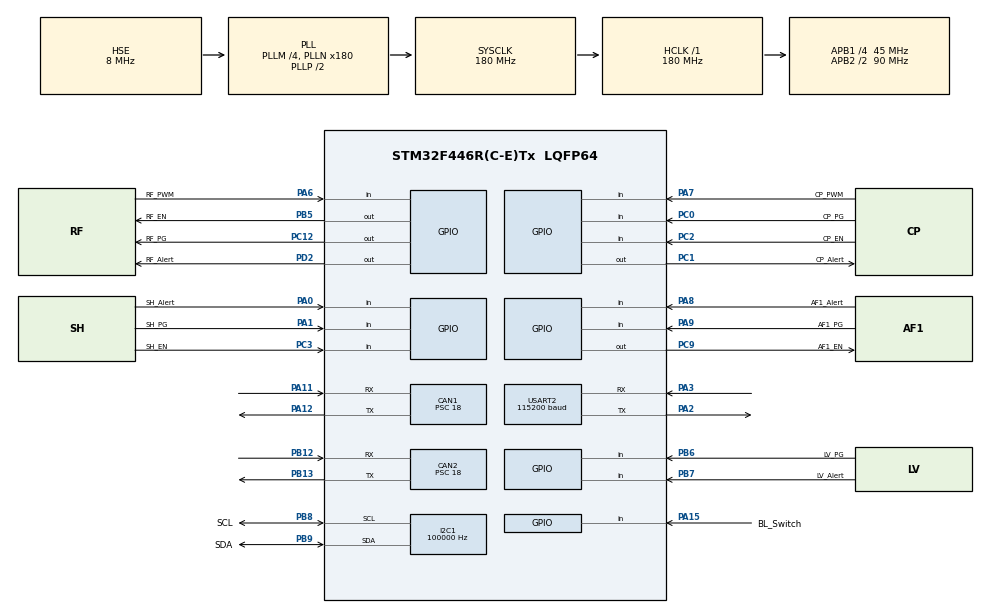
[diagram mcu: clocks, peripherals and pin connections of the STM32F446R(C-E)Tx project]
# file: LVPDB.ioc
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CAN1.BS1=CAN_BS1_3TQ
CAN1.CalculateBaudRate=500000
CAN1.CalculateTimeBit=2000
CAN1.CalculateTimeQuantum=400.0
CAN1.Mode=CAN_MODE_NORMAL
CAN1.Prescaler=18
CAN2.BS1=CAN_BS1_3TQ
CAN2.CalculateBaudRate=500000
CAN2.CalculateTimeBit=2000
CAN2.CalculateTimeQuantum=400.0
CAN2.Mode=CAN_MODE_NORMAL
CAN2.Prescaler=18
Dma.Request0=USART2_RX
Dma.Request1=USART2_TX
Dma.USART2_RX.0.Direction=DMA_PERIPH_TO_MEMORY
Dma.USART2_RX.0.FIFOMode=DMA_FIFOMODE_DISABLE
Dma.USART2_RX.0.Instance=DMA1_Stream5
Dma.USART2_RX.0.MemDataAlignment=DMA_MDATAALIGN_BYTE
Dma.USART2_RX.0.MemInc=DMA_MINC_ENABLE
Dma.USART2_RX.0.Mode=DMA_CIRCULAR
Dma.USART2_RX.0.PeriphDataAlignment=DMA_PDATAALIGN_BYTE
Dma.USART2_RX.0.PeriphInc=DMA_PINC_DISABLE
Dma.USART2_RX.0.Priority=DMA_PRIORITY_LOW
Dma.USART2_TX.1.Direction=DMA_MEMORY_TO_PERIPH
Dma.USART2_TX.1.FIFOMode=DMA_FIFOMODE_DISABLE
Dma.USART2_TX.1.Instance=DMA1_Stream6
Dma.USART2_TX.1.MemDataAlignment=DMA_MDATAALIGN_BYTE
Dma.USART2_TX.1.MemInc=DMA_MINC_ENABLE
Dma.USART2_TX.1.Mode=DMA_NORMAL
Dma.USART2_TX.1.PeriphDataAlignment=DMA_PDATAALIGN_BYTE
Dma.USART2_TX.1.PeriphInc=DMA_PINC_DISABLE
Dma.USART2_TX.1.Priority=DMA_PRIORITY_LOW
FREERTOS.BinarySemaphores01=uartTxSem,Dynamic,NULL,Available
FREERTOS.CountingSemaphores01=canTxMailboxSem,3,Dynamic,NULL,3
FREERTOS.Mutexes01=logMutex,Dynamic,NULL,Available;uartTxMutex,Dynamic,NULL,Available;canTxMutex,Dynamic,NULL,Available;canRxMutex,Dynamic,NULL,Available;FEB_I2C_mutex,Dynamic,NULL,Available;tpsDataMutex,Dynamic,NULL,Available
FREERTOS.Queues01=canTxQueue,16,FEB_CAN_Message_t,0,Dynamic,NULL,NULL;canRxQueue,32,FEB_CAN_Message_t,0,Dynamic,NULL,NULL;uartRxQueue,8,FEB_UART_RxQueueMsg_t,0,Dynamic,NULL,NULL
FREERTOS.Tasks01=uartRxTask,16,256,StartUartRxTask,As weak,NULL,Dynamic,NULL,NULL;tpsTask,25,192,StartTpsTask,As weak,NULL,Dynamic,NULL,NULL;canRxTask,24,192,StartCanRxTask,As weak,NULL,Dynamic,NULL,NULL;canTxTask,32,192,StartCanTxTask,As weak,NULL,Dynamic,NULL,NULL;canPubTask,24,256,StartCanPubTask,As weak,NULL,Dynamic,NULL,NULL;pwmTask,8,128,StartPwmTask,As weak,NULL,Dynamic,NULL,NULL
I2C1.ClockSpeed=100000
Mcu.Family=STM32F4
Mcu.Name=STM32F446R(C-E)Tx
Mcu.Package=LQFP64
NVIC.CAN1_RX0_IRQn=true\:5\:0\:false\:false\:true\:true\:true\:true\:true
NVIC.CAN1_RX1_IRQn=true\:5\:0\:false\:false\:true\:true\:true\:true\:true
NVIC.CAN1_SCE_IRQn=true\:5\:0\:false\:false\:true\:true\:true\:true\:true
NVIC.CAN1_TX_IRQn=true\:5\:0\:false\:false\:true\:true\:true\:true\:true
NVIC.CAN2_RX0_IRQn=true\:5\:0\:false\:false\:true\:true\:true\:true\:true
NVIC.CAN2_RX1_IRQn=true\:5\:0\:false\:false\:true\:true\:true\:true\:true
NVIC.CAN2_SCE_IRQn=true\:5\:0\:false\:false\:true\:true\:true\:true\:true
NVIC.CAN2_TX_IRQn=true\:5\:0\:false\:false\:true\:true\:true\:true\:true
NVIC.DMA1_Stream5_IRQn=true\:5\:0\:false\:false\:true\:true\:false\:true\:true
NVIC.DMA1_Stream6_IRQn=true\:5\:0\:false\:false\:true\:true\:false\:true\:true
NVIC.PriorityGroup=NVIC_PRIORITYGROUP_4
NVIC.TIM1_UP_TIM10_IRQn=true\:5\:0\:false\:false\:true\:true\:true\:true\:true
NVIC.TIM6_DAC_IRQn=true\:15\:0\:false\:false\:true\:false\:false\:true\:true
NVIC.TimeBase=TIM6_DAC_IRQn
NVIC.TimeBaseIP=TIM6
NVIC.USART2_IRQn=true\:5\:0\:false\:false\:true\:true\:true\:true\:true
PA0-WKUP.GPIO_Label=SH_Alert
PA0-WKUP.Signal=GPIO_Input
PA1.GPIO_Label=SH_PG
PA1.Signal=GPIO_Input
PA11.Mode=CAN_Activate
PA11.Signal=CAN1_RX
PA12.Mode=CAN_Activate
PA12.Signal=CAN1_TX
PA13.Mode=Serial_Wire
PA13.Signal=SYS_JTMS-SWDIO
PA14.Mode=Serial_Wire
PA14.Signal=SYS_JTCK-SWCLK
PA15.GPIO_Label=BL_Switch
PA15.Signal=GPIO_Input
PA2.Mode=Asynchronous
PA2.Signal=USART2_TX
PA3.Mode=Asynchronous
PA3.Signal=USART2_RX
PA6.GPIO_Label=RF_PWM
PA6.Signal=GPIO_Input
PA7.GPIO_Label=CP_PWM
PA7.Signal=GPIO_Input
PA8.GPIO_Label=AF1_Alert
PA8.Signal=GPIO_Input
PA9.GPIO_Label=AF1_PG
PA9.GPIO_PuPd=GPIO_PULLDOWN
PA9.Signal=GPIO_Input
PB12.Mode=CAN_Activate
PB12.Signal=CAN2_RX
PB13.Mode=CAN_Activate
PB13.Signal=CAN2_TX
PB5.GPIO_Label=RF_EN
PB5.Signal=GPIO_Output
PB6.GPIO_Label=LV_PG
PB6.GPIO_PuPd=GPIO_PULLDOWN
PB6.Signal=GPIO_Input
PB7.GPIO_Label=LV_Alert
PB7.Signal=GPIO_Input
PB8.GPIO_Label=SCL
PB8.Mode=I2C
PB8.Signal=I2C1_SCL
PB9.GPIO_Label=SDA
PB9.Mode=I2C
PB9.Signal=I2C1_SDA
PC0.GPIO_Label=CP_PG
PC0.Signal=GPIO_Input
PC1.GPIO_Label=CP_Alert
PC1.Signal=GPIO_Output
PC12.GPIO_Label=RF_PG
PC12.Signal=GPIO_Output
PC14-OSC32_IN.Mode=LSE-External-Oscillator
PC14-OSC32_IN.Signal=RCC_OSC32_IN
PC15-OSC32_OUT.Mode=LSE-External-Oscillator
PC15-OSC32_OUT.Signal=RCC_OSC32_OUT
PC2.GPIO_Label=CP_EN
PC2.GPIO_PuPd=GPIO_PULLDOWN
PC2.Signal=GPIO_Input
PC3.GPIO_Label=SH_EN
PC3.Signal=GPIO_Input
PC9.GPIO_Label=AF1_EN
PC9.Signal=GPIO_Output
PD2.GPIO_Label=RF_Alert
PD2.Signal=GPIO_Output
PH0-OSC_IN.Mode=HSE-External-Oscillator
PH0-OSC_IN.Signal=RCC_OSC_IN
PH1-OSC_OUT.Mode=HSE-External-Oscillator
PH1-OSC_OUT.Signal=RCC_OSC_OUT
ProjectManager.HeapSize=0x200
ProjectManager.StackSize=0x400
ProjectManager.TargetToolchain=CMake
RCC.AHBFreq_Value=180000000
RCC.APB1CLKDivider=RCC_HCLK_DIV4
RCC.APB1Freq_Value=45000000
RCC.APB1TimFreq_Value=90000000
RCC.APB2CLKDivider=RCC_HCLK_DIV2
RCC.APB2Freq_Value=90000000
RCC.APB2TimFreq_Value=180000000
RCC.CortexFreq_Value=180000000
RCC.HCLKFreq_Value=180000000
RCC.HSE_VALUE=8000000
RCC.PLLM=4
RCC.PLLN=180
RCC.PLLSourceVirtual=RCC_PLLSOURCE_HSE
RCC.SYSCLKFreq_VALUE=180000000
RCC.SYSCLKSource=RCC_SYSCLKSOURCE_PLLCLK
RCC.USBFreq_Value=180000000
RCC.VCOOutputFreq_Value=360000000
TIM1.AutoReloadPreload=TIM_AUTORELOAD_PRELOAD_ENABLE
TIM1.Period=10000
TIM1.Prescaler=180
USART2.BaudRate=115200
USART2.VirtualMode=VM_ASYNC
VP_FREERTOS_VS_CMSIS_V2.Mode=CMSIS_V2
VP_SYS_VS_tim6.Mode=TIM6
VP_TIM1_VS_ClockSourceINT.Mode=Internal
board=custom

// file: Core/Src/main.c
/* USER CODE BEGIN Header */
/**
 ******************************************************************************
 * @file           : main.c
 * @brief          : Main program body
 ******************************************************************************
 * @attention
 *
 * Copyright (c) 2025 STMicroelectronics.
 * All rights reserved.
 *
 * This software is licensed under terms that can be found in the LICENSE file
 * in the root directory of this software component.
 * If no LICENSE file comes with this software, it is provided AS-IS.
 *
 ******************************************************************************
 */
/* USER CODE END Header */
#include "main.h"
#include "cmsis_os.h"
#include "can.h"
#include "dma.h"
#include "i2c.h"
#include "tim.h"
#include "usart.h"
#include "gpio.h"

/* USER CODE BEGIN Includes */
#include "LVPDB_Main.h"
/* USER CODE END Includes */

void SystemClock_Config(void);
void MX_FREERTOS_Init(void);

int main(void)
{

  /* MCU Configuration--------------------------------------------------------*/

  /* Reset of all peripherals, Initializes the Flash interface and the Systick. */
  HAL_Init();

  /* Configure the system clock */
  SystemClock_Config();

  /* Initialize all configured peripherals */
  MX_GPIO_Init();
  MX_DMA_Init();
  MX_USART2_UART_Init();
  MX_CAN1_Init();
  MX_CAN2_Init();
  MX_I2C1_Init();
  MX_TIM1_Init();

  /* Init scheduler */
  osKernelInitialize();  /* Call init function for freertos objects (in cmsis_os2.c) */
  MX_FREERTOS_Init();

  /* Start scheduler */
  osKernelStart();

  /* We should never get here as control is now taken by the scheduler */

  /* Infinite loop */
  while (1)
  {

  }
}

void SystemClock_Config(void)
{
  RCC_OscInitTypeDef RCC_OscInitStruct = {0};
  RCC_ClkInitTypeDef RCC_ClkInitStruct = {0};

  /** Configure the main internal regulator output voltage
  */
  __HAL_RCC_PWR_CLK_ENABLE();
  __HAL_PWR_VOLTAGESCALING_CONFIG(PWR_REGULATOR_VOLTAGE_SCALE1);

  /** Initializes the RCC Oscillators according to the specified parameters
  * in the RCC_OscInitTypeDef structure.
  */
  RCC_OscInitStruct.OscillatorType = RCC_OSCILLATORTYPE_HSE;
  RCC_OscInitStruct.HSEState = RCC_HSE_ON;
  RCC_OscInitStruct.PLL.PLLState = RCC_PLL_ON;
  RCC_OscInitStruct.PLL.PLLSource = RCC_PLLSOURCE_HSE;
  RCC_OscInitStruct.PLL.PLLM = 4;
  RCC_OscInitStruct.PLL.PLLN = 180;
  RCC_OscInitStruct.PLL.PLLP = RCC_PLLP_DIV2;
  RCC_OscInitStruct.PLL.PLLQ = 2;
  RCC_OscInitStruct.PLL.PLLR = 2;
  if (HAL_RCC_OscConfig(&RCC_OscInitStruct) != HAL_OK)
  {
    Error_Handler();
  }

  /** Activate the Over-Drive mode
  */
  if (HAL_PWREx_EnableOverDrive() != HAL_OK)
  {
    Error_Handler();
  }

  /** Initializes the CPU, AHB and APB buses clocks
  */
  RCC_ClkInitStruct.ClockType = RCC_CLOCKTYPE_HCLK|RCC_CLOCKTYPE_SYSCLK
                              |RCC_CLOCKTYPE_PCLK1|RCC_CLOCKTYPE_PCLK2;
  RCC_ClkInitStruct.SYSCLKSource = RCC_SYSCLKSOURCE_PLLCLK;
  RCC_ClkInitStruct.AHBCLKDivider = RCC_SYSCLK_DIV1;
  RCC_ClkInitStruct.APB1CLKDivider = RCC_HCLK_DIV4;
  RCC_ClkInitStruct.APB2CLKDivider = RCC_HCLK_DIV2;

  if (HAL_RCC_ClockConfig(&RCC_ClkInitStruct, FLASH_LATENCY_5) != HAL_OK)
  {
    Error_Handler();
  }
}

void HAL_TIM_PeriodElapsedCallback(TIM_HandleTypeDef *htim)
{
  if (htim->Instance == TIM6)
  {
    HAL_IncTick();
  }
}

void Error_Handler(void)
{
  __disable_irq();
  while (1)
  {
  }
}

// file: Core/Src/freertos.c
/* USER CODE BEGIN Header */
/**
  ******************************************************************************
  * File Name          : freertos.c
  * Description        : Code for freertos applications
  ******************************************************************************
  * @attention
  *
  * Copyright (c) 2026 STMicroelectronics.
  * All rights reserved.
  *
  * This software is licensed under terms that can be found in the LICENSE file
  * in the root directory of this software component.
  * If no LICENSE file comes with this software, it is provided AS-IS.
  *
  ******************************************************************************
  */
/* USER CODE END Header */

#include "FreeRTOS.h"
#include "task.h"
#include "main.h"
#include "cmsis_os.h"

/* USER CODE BEGIN Includes */
#include "LVPDB_Main.h"
#include "feb_uart.h"
#include "feb_console.h"
#include "feb_can_lib.h"
#include <stdio.h>
/* USER CODE END Includes */

/* Definitions for uartRxTask */
osThreadId_t uartRxTaskHandle;
const osThreadAttr_t uartRxTask_attributes = {
  .name = "uartRxTask",
  .stack_size = 256 * 4,
  .priority = (osPriority_t) osPriorityBelowNormal,
};
/* Definitions for tpsTask */
osThreadId_t tpsTaskHandle;
const osThreadAttr_t tpsTask_attributes = {
  .name = "tpsTask",
  .stack_size = 192 * 4,
  .priority = (osPriority_t) osPriorityNormal1,
};
/* Definitions for canRxTask */
osThreadId_t canRxTaskHandle;
const osThreadAttr_t canRxTask_attributes = {
  .name = "canRxTask",
  .stack_size = 192 * 4,
  .priority = (osPriority_t) osPriorityNormal,
};
/* Definitions for canTxTask */
osThreadId_t canTxTaskHandle;
const osThreadAttr_t canTxTask_attributes = {
  .name = "canTxTask",
  .stack_size = 192 * 4,
  .priority = (osPriority_t) osPriorityAboveNormal,
};
/* Definitions for canPubTask */
osThreadId_t canPubTaskHandle;
const osThreadAttr_t canPubTask_attributes = {
  .name = "canPubTask",
  .stack_size = 256 * 4,
  .priority = (osPriority_t) osPriorityNormal,
};
/* Definitions for pwmTask */
osThreadId_t pwmTaskHandle;
const osThreadAttr_t pwmTask_attributes = {
  .name = "pwmTask",
  .stack_size = 128 * 4,
  .priority = (osPriority_t) osPriorityLow,
};
/* Definitions for canTxQueue */
osMessageQueueId_t canTxQueueHandle;
const osMessageQueueAttr_t canTxQueue_attributes = {
  .name = "canTxQueue"
};
/* Definitions for canRxQueue */
osMessageQueueId_t canRxQueueHandle;
const osMessageQueueAttr_t canRxQueue_attributes = {
  .name = "canRxQueue"
};
/* Definitions for uartRxQueue */
osMessageQueueId_t uartRxQueueHandle;
const osMessageQueueAttr_t uartRxQueue_attributes = {
  .name = "uartRxQueue"
};
/* Definitions for logMutex */
osMutexId_t logMutexHandle;
const osMutexAttr_t logMutex_attributes = {
  .name = "logMutex"
};
/* Definitions for uartTxMutex */
osMutexId_t uartTxMutexHandle;
const osMutexAttr_t uartTxMutex_attributes = {
  .name = "uartTxMutex"
};
/* Definitions for canTxMutex */
osMutexId_t canTxMutexHandle;
const osMutexAttr_t canTxMutex_attributes = {
  .name = "canTxMutex"
};
/* Definitions for canRxMutex */
osMutexId_t canRxMutexHandle;
const osMutexAttr_t canRxMutex_attributes = {
  .name = "canRxMutex"
};
/* Definitions for FEB_I2C_mutex */
osMutexId_t FEB_I2C_mutexHandle;
const osMutexAttr_t FEB_I2C_mutex_attributes = {
  .name = "FEB_I2C_mutex"
};
/* Definitions for tpsDataMutex */
osMutexId_t tpsDataMutexHandle;
const osMutexAttr_t tpsDataMutex_attributes = {
  .name = "tpsDataMutex"
};
/* Definitions for uartTxSem */
osSemaphoreId_t uartTxSemHandle;
const osSemaphoreAttr_t uartTxSem_attributes = {
  .name = "uartTxSem"
};
/* Definitions for canTxMailboxSem */
osSemaphoreId_t canTxMailboxSemHandle;
const osSemaphoreAttr_t canTxMailboxSem_attributes = {
  .name = "canTxMailboxSem"
};

void StartUartRxTask(void *argument);
void StartTpsTask(void *argument);
void StartCanRxTask(void *argument);
void StartCanTxTask(void *argument);
void StartCanPubTask(void *argument);
void StartPwmTask(void *argument);

void MX_FREERTOS_Init(void); /* (MISRA C 2004 rule 8.1) */

void MX_FREERTOS_Init(void) {
  /* Create the mutex(es) */
  /* creation of logMutex */
  logMutexHandle = osMutexNew(&logMutex_attributes);

  /* creation of uartTxMutex */
  uartTxMutexHandle = osMutexNew(&uartTxMutex_attributes);

  /* creation of canTxMutex */
  canTxMutexHandle = osMutexNew(&canTxMutex_attributes);

  /* creation of canRxMutex */
  canRxMutexHandle = osMutexNew(&canRxMutex_attributes);

  /* creation of FEB_I2C_mutex */
  FEB_I2C_mutexHandle = osMutexNew(&FEB_I2C_mutex_attributes);

  /* creation of tpsDataMutex */
  tpsDataMutexHandle = osMutexNew(&tpsDataMutex_attributes);

  /* Create the semaphores(s) */
  /* creation of uartTxSem */
  uartTxSemHandle = osSemaphoreNew(1, 1, &uartTxSem_attributes);

  /* creation of canTxMailboxSem */
  canTxMailboxSemHandle = osSemaphoreNew(3, 3, &canTxMailboxSem_attributes);

  /* Create the queue(s) */
  /* creation of canTxQueue */
  canTxQueueHandle = osMessageQueueNew (16, sizeof(FEB_CAN_Message_t), &canTxQueue_attributes);

  /* creation of canRxQueue */
  canRxQueueHandle = osMessageQueueNew (32, sizeof(FEB_CAN_Message_t), &canRxQueue_attributes);

  /* creation of uartRxQueue */
  uartRxQueueHandle = osMessageQueueNew (8, sizeof(FEB_UART_RxQueueMsg_t), &uartRxQueue_attributes);

  /* Create the thread(s) */
  /* creation of uartRxTask */
  uartRxTaskHandle = osThreadNew(StartUartRxTask, NULL, &uartRxTask_attributes);

  /* creation of tpsTask */
  tpsTaskHandle = osThreadNew(StartTpsTask, NULL, &tpsTask_attributes);

  /* creation of canRxTask */
  canRxTaskHandle = osThreadNew(StartCanRxTask, NULL, &canRxTask_attributes);

  /* creation of canTxTask */
  canTxTaskHandle = osThreadNew(StartCanTxTask, NULL, &canTxTask_attributes);

  /* creation of canPubTask */
  canPubTaskHandle = osThreadNew(StartCanPubTask, NULL, &canPubTask_attributes);

  /* creation of pwmTask */
  pwmTaskHandle = osThreadNew(StartPwmTask, NULL, &pwmTask_attributes);

  /* USER CODE BEGIN RTOS_EVENTS */
  /* add events, ... */
  LVPDB_Init();
  /* USER CODE END RTOS_EVENTS */

}

__weak void StartUartRxTask(void *argument)
{
  for(;;)
  {
    osDelay(1);
  }
}

__weak void StartTpsTask(void *argument)
{
  for(;;)
  {
    osDelay(1);
  }
}

__weak void StartCanRxTask(void *argument)
{
  for(;;)
  {
    osDelay(1);
  }
}

__weak void StartCanTxTask(void *argument)
{
  for(;;)
  {
    osDelay(1);
  }
}

__weak void StartCanPubTask(void *argument)
{
  for(;;)
  {
    osDelay(1);
  }
}

__weak void StartPwmTask(void *argument)
{
  for(;;)
  {
    osDelay(1);
  }
}
